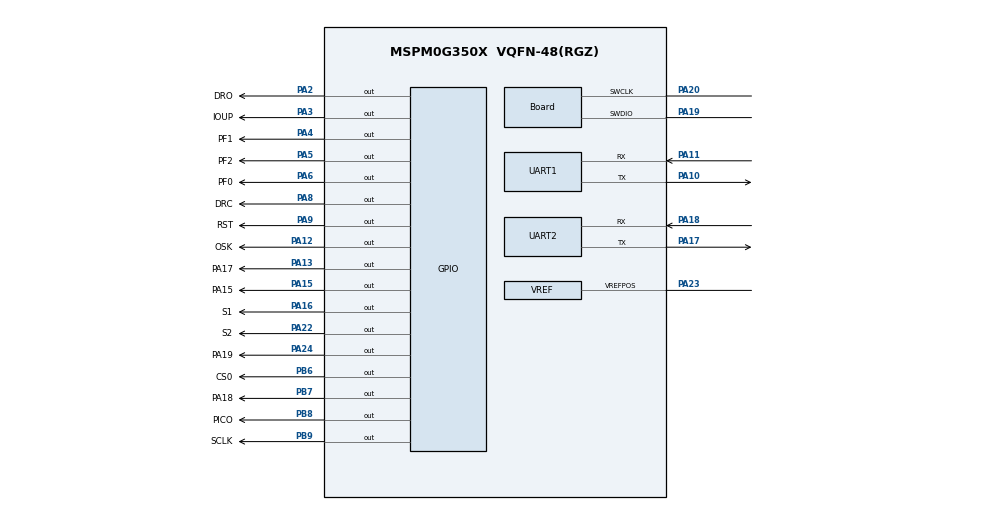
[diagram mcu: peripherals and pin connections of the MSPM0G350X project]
/**
 * @cliArgs --device "MSPM0G350X" --package "VQFN-48(RGZ)" --part "Default" --product "mspm0_sdk@1.20.01.06"
 * @versions {"tool":"1.18.1+3343"}
 */

/**
 * Import the modules used in this configuration.
 */
const ADC12         = scripting.addModule("/ti/driverlib/ADC12", {}, false);
const ADC121        = ADC12.addInstance();
const Board         = scripting.addModule("/ti/driverlib/Board");
const GPIO          = scripting.addModule("/ti/driverlib/GPIO", {}, false);
const GPIO1         = GPIO.addInstance();
const GPIO2         = GPIO.addInstance();
const SYSCTL        = scripting.addModule("/ti/driverlib/SYSCTL");
const TIMER         = scripting.addModule("/ti/driverlib/TIMER", {}, false);
const TIMER1        = TIMER.addInstance();
const UART          = scripting.addModule("/ti/driverlib/UART", {}, false);
const UART1         = UART.addInstance();
const UART2         = UART.addInstance();
const VREF          = scripting.addModule("/ti/driverlib/VREF");
const ProjectConfig = scripting.addModule("/ti/project_config/ProjectConfig");

/**
 * Write custom configuration values to the imported modules.
 */
const divider4       = system.clockTree["PLL_CLK0_DIV"];
divider4.divideValue = 4;

const divider7       = system.clockTree["PLL_PDIV"];
divider7.divideValue = 8;

const gate7  = system.clockTree["MFCLKGATE"];
gate7.enable = true;

const gate8  = system.clockTree["MFPCLKGATE"];
gate8.enable = true;

const multiplier2         = system.clockTree["PLL_QDIV"];
multiplier2.multiplyValue = 40;

const pinFunction4     = system.clockTree["HFXT"];
pinFunction4.inputFreq = 8;

ADC121.$name                      = "ADC12_0";
ADC121.repeatMode                 = true;
ADC121.sampClkDiv                 = "DL_ADC12_CLOCK_DIVIDE_8";
ADC121.sampleTime0                = "125us";
ADC121.samplingOperationMode      = "sequence";
ADC121.endAdd                     = 2;
ADC121.adcMem1chansel             = "DL_ADC12_INPUT_CHAN_1";
ADC121.adcMem2chansel             = "DL_ADC12_INPUT_CHAN_2";
ADC121.adcMem1vref                = "VREF";
ADC121.adcMem2vref                = "VREF";
ADC121.enabledInterrupts          = ["DL_ADC12_INTERRUPT_MEM0_RESULT_LOADED","DL_ADC12_INTERRUPT_MEM1_RESULT_LOADED","DL_ADC12_INTERRUPT_MEM2_RESULT_LOADED"];
ADC121.peripheral.$assign         = "ADC0";
ADC121.peripheral.adcPin0.$assign = "PA27";
ADC121.peripheral.adcPin1.$assign = "PA26";
ADC121.peripheral.adcPin2.$assign = "PA25";
ADC121.adcPin0Config.$name        = "ti_driverlib_gpio_GPIOPinGeneric0";
ADC121.adcPin1Config.$name        = "ti_driverlib_gpio_GPIOPinGeneric3";
ADC121.adcPin2Config.$name        = "ti_driverlib_gpio_GPIOPinGeneric4";

Board.peripheral.$assign          = "DEBUGSS";
Board.peripheral.swclkPin.$assign = "PA20";
Board.peripheral.swdioPin.$assign = "PA19";

GPIO1.$name                          = "DAC";
GPIO1.associatedPins.create(16);
GPIO1.associatedPins[0].$name        = "PWR";
GPIO1.associatedPins[1].$name        = "DRH";
GPIO1.associatedPins[2].$name        = "DRO";
GPIO1.associatedPins[2].pin.$assign  = "PA2";
GPIO1.associatedPins[3].$name        = "IOUP";
GPIO1.associatedPins[3].pin.$assign  = "PA3";
GPIO1.associatedPins[4].$name        = "PF1";
GPIO1.associatedPins[4].pin.$assign  = "PA4";
GPIO1.associatedPins[5].$name        = "PF2";
GPIO1.associatedPins[5].pin.$assign  = "PA5";
GPIO1.associatedPins[6].$name        = "PF0";
GPIO1.associatedPins[6].pin.$assign  = "PA6";
GPIO1.associatedPins[7].$name        = "OSK";
GPIO1.associatedPins[7].pin.$assign  = "PA12";
GPIO1.associatedPins[8].$name        = "DRC";
GPIO1.associatedPins[8].pin.$assign  = "PA8";
GPIO1.associatedPins[9].$name        = "RST";
GPIO1.associatedPins[9].pin.$assign  = "PA9";
GPIO1.associatedPins[10].$name       = "SCLK";
GPIO1.associatedPins[10].pin.$assign = "PB9";
GPIO1.associatedPins[11].$name       = "PICO";
GPIO1.associatedPins[11].pin.$assign = "PB8";
GPIO1.associatedPins[12].$name       = "CS0";
GPIO1.associatedPins[12].pin.$assign = "PB6";
GPIO1.associatedPins[13].$name       = "PA15";
GPIO1.associatedPins[13].pin.$assign = "PA15";
GPIO1.associatedPins[14].$name       = "PA17";
GPIO1.associatedPins[14].pin.$assign = "PA13";
GPIO1.associatedPins[15].$name       = "PA18";
GPIO1.associatedPins[15].pin.$assign = "PB7";

GPIO2.$name                              = "SW";
GPIO2.associatedPins.create(3);
GPIO2.associatedPins[0].$name            = "S1";
GPIO2.associatedPins[0].internalResistor = "PULL_DOWN";
GPIO2.associatedPins[0].ioStructure      = "SD";
GPIO2.associatedPins[0].pin.$assign      = "PA16";
GPIO2.associatedPins[1].$name            = "S2";
GPIO2.associatedPins[1].internalResistor = "PULL_DOWN";
GPIO2.associatedPins[1].ioStructure      = "SD";
GPIO2.associatedPins[1].pin.$assign      = "PA22";
GPIO2.associatedPins[2].$name            = "PA19";
GPIO2.associatedPins[2].internalResistor = "PULL_DOWN";
GPIO2.associatedPins[2].pin.$assign      = "PA24";

SYSCTL.MFCLKEn     = true;
SYSCTL.MFPCLKEn    = true;
SYSCTL.clockTreeEn = true;

TIMER1.$name           = "TIMER_0";
TIMER1.timerClkSrc     = "MFCLK";
TIMER1.timerStartTimer = true;
TIMER1.interrupts      = ["ZERO"];
TIMER1.timerMode       = "PERIODIC";
TIMER1.timerPeriod     = "10 ms";

UART1.$name                    = "UART_0";
UART1.enabledInterrupts        = ["RX"];
UART1.uartClkSrc               = "MFCLK";
UART1.targetBaudRate           = 115200;
UART1.peripheral.$assign       = "UART0";
UART1.peripheral.rxPin.$assign = "PA11";
UART1.peripheral.txPin.$assign = "PA10";
UART1.txPinConfig.$name        = "ti_driverlib_gpio_GPIOPinGeneric6";
UART1.rxPinConfig.$name        = "ti_driverlib_gpio_GPIOPinGeneric7";

UART2.$name                    = "UART_1";
UART2.uartClkSrc               = "MFCLK";
UART2.targetBaudRate           = 115200;
UART2.enabledInterrupts        = ["RX"];
UART2.peripheral.rxPin.$assign = "PA18";
UART2.peripheral.txPin.$assign = "PA17";
UART2.txPinConfig.$name        = "ti_driverlib_gpio_GPIOPinGeneric2";
UART2.rxPinConfig.$name        = "ti_driverlib_gpio_GPIOPinGeneric5";

VREF.basicIntVolt                  = "DL_VREF_BUFCONFIG_OUTPUT_2_5V";
VREF.advClockConfigEnable          = true;
VREF.advClkSrc                     = "DL_VREF_CLOCK_BUSCLK";
VREF.checkVREFReady                = true;
VREF.peripheral.$assign            = "VREF";
VREF.peripheral.vrefPosPin.$assign = "PA23";
VREF.vrefPosPinConfig.$name        = "ti_driverlib_gpio_GPIOPinGeneric1";

ProjectConfig.deviceSpin = "MSPM0G3507";
scripting.suppress("Migrating requires going through the Switch Board or Device menu in the Device View section\\.", ProjectConfig, "deviceSpin");

/**
 * Pinmux solution for unlocked pins/peripherals. This ensures that minor changes to the automatic solver in a future
 * version of the tool will not impact the pinmux you originally saw.  These lines can be completely deleted in order to
 * re-solve from scratch.
 */
GPIO1.associatedPins[0].pin.$suggestSolution = "PA0";
GPIO1.associatedPins[1].pin.$suggestSolution = "PA1";
TIMER1.peripheral.$suggestSolution           = "TIMA0";
UART2.peripheral.$suggestSolution            = "UART1";
